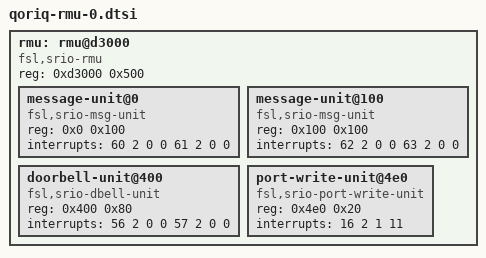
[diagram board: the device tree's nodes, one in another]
rmu: rmu@d3000 {
	#address-cells = <1>;
	#size-cells = <1>;
	compatible = "fsl,srio-rmu";
	reg = <0xd3000 0x500>;
	ranges = <0x0 0xd3000 0x500>;
	message-unit@0 {
		compatible = "fsl,srio-msg-unit";
		reg = <0x0 0x100>;
		interrupts = <
			60 2 0 0   
			61 2 0 0>; 
	};
	message-unit@100 {
		compatible = "fsl,srio-msg-unit";
		reg = <0x100 0x100>;
		interrupts = <
			62 2 0 0   
			63 2 0 0>; 
	};
	doorbell-unit@400 {
		compatible = "fsl,srio-dbell-unit";
		reg = <0x400 0x80>;
		interrupts = <
			56 2 0 0   
			57 2 0 0>; 
	};
	port-write-unit@4e0 {
		compatible = "fsl,srio-port-write-unit";
		reg = <0x4e0 0x20>;
		interrupts = <16 2 1 11>;
	};
};
